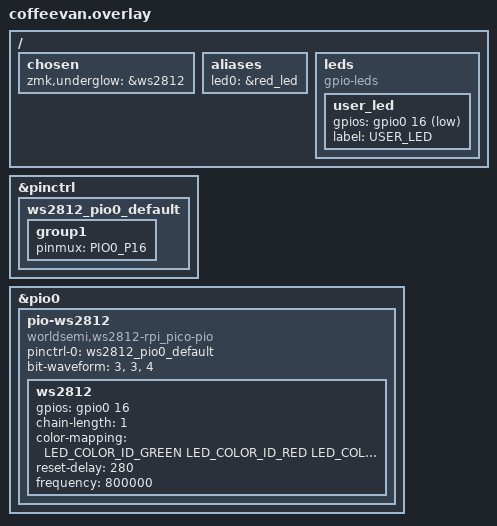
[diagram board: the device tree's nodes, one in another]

#include <dt-bindings/led/led.h>
#include <dt-bindings/pinctrl/rpi-pico-rp2040-pinctrl.h>

&pinctrl {
    ws2812_pio0_default: ws2812_pio0_default {
        group1 {
            pinmux = <PIO0_P16>;
        };
    };
};

&pio0 {
	status = "okay";

	pio-ws2812 {
		compatible = "worldsemi,ws2812-rpi_pico-pio";
		status = "okay";
		pinctrl-0 = <&ws2812_pio0_default>;
		pinctrl-names = "default";
		bit-waveform = <3>, <3>, <4>;

		ws2812: ws2812 {
			status = "okay";
			gpios = <&gpio0 16 GPIO_ACTIVE_HIGH>;
			chain-length = <1>;
			color-mapping = <LED_COLOR_ID_GREEN
					 LED_COLOR_ID_RED
					 LED_COLOR_ID_BLUE>;
			reset-delay = <280>;
			frequency = <800000>;
		};
	};
};

/ {
    chosen {
        zmk,underglow = &ws2812;
    };
    
	aliases {
		led0 = &red_led;
	};
    
	leds {
		compatible = "gpio-leds";

		user_led: user_led {
			gpios = <&gpio0 16 GPIO_ACTIVE_LOW>;
			label = "USER_LED";
		};
	};
};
